# iom480ae register map
Registers are 32-bit, access not given, no defined reset value unless marked. A register's access mark holds for its fields unless they carry their own. Addresses are absolute; registers are grouped by the start of their names; [hi:lo] are bit positions; {n}, {i} and the like mark numbered series.

## QEI0
0x400B0000 QEI0_QEI_CNT
0x400B0004 QEI0_QEI_CNTHOLD
0x400B0008 QEI0_QEI_CNTLATCH
0x400B000C QEI0_QEI_CNTCMP
0x400B0014 QEI0_QEI_CNTMAX
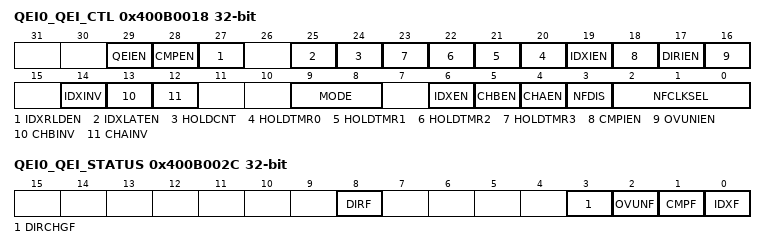
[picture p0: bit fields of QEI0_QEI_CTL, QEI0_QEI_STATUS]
0x400B0018 QEI0_QEI_CTL
  [29] QEIEN, [28] CMPEN, [27] IDXRLDEN, [25] IDXLATEN, [24] HOLDCNT, [n+20] HOLDTMR{n} (n=0..3), [19] IDXIEN, [18] CMPIEN, [17] DIRIEN, [16] OVUNIEN, [14] IDXINV, [13] CHBINV, [12] CHAINV, [9:8] MODE, [6] IDXEN, [5] CHBEN, [4] CHAEN, [3] NFDIS, [2:0] NFCLKSEL
0x400B002C QEI0_QEI_STATUS
  [8] DIRF, [3] DIRCHGF, [2] OVUNF, [1] CMPF, [0] IDXF

## QEI1
0x400B1000 QEI1_QEI_CNT
0x400B1004 QEI1_QEI_CNTHOLD
0x400B1008 QEI1_QEI_CNTLATCH
0x400B100C QEI1_QEI_CNTCMP
0x400B1014 QEI1_QEI_CNTMAX
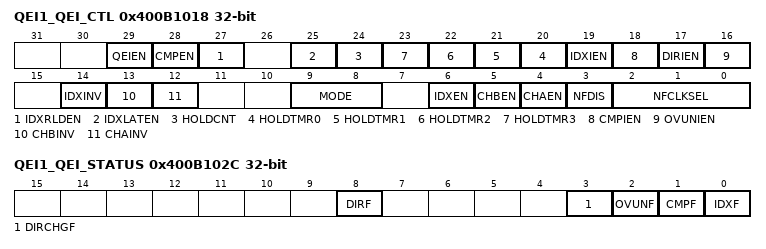
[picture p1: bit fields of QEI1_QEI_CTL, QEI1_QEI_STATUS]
0x400B1018 QEI1_QEI_CTL
  [29] QEIEN, [28] CMPEN, [27] IDXRLDEN, [25] IDXLATEN, [24] HOLDCNT, [n+20] HOLDTMR{n} (n=0..3), [19] IDXIEN, [18] CMPIEN, [17] DIRIEN, [16] OVUNIEN, [14] IDXINV, [13] CHBINV, [12] CHAINV, [9:8] MODE, [6] IDXEN, [5] CHBEN, [4] CHAEN, [3] NFDIS, [2:0] NFCLKSEL
0x400B102C QEI1_QEI_STATUS
  [8] DIRF, [3] DIRCHGF, [2] OVUNF, [1] CMPF, [0] IDXF

## ECAP0
0x400B4000 ECAP0_ECAP_CNT
  [23:0] CNT
{0x400B4004+4i} ECAP0_ECAP_HLD{i} (i=0..2)
  [23:0] HOLD
0x400B4010 ECAP0_ECAP_CNTCMP
  [23:0] CNTCMP
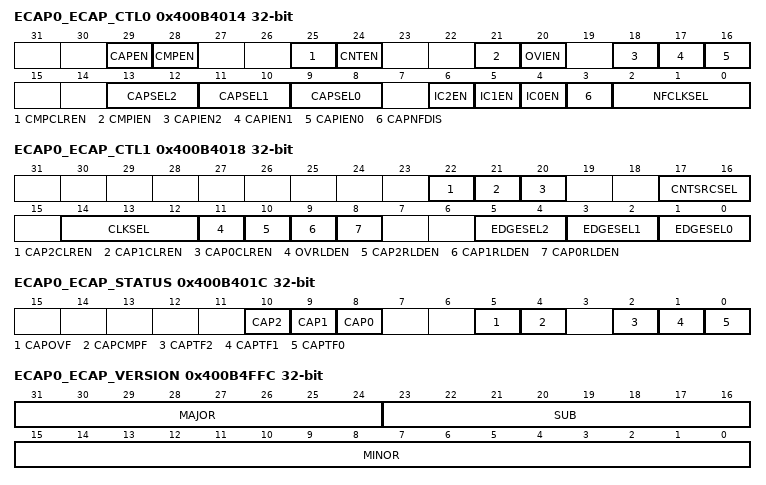
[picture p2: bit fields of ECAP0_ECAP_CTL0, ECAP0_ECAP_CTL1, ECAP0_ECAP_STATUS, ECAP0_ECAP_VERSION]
0x400B4014 ECAP0_ECAP_CTL0
  [29] CAPEN, [28] CMPEN, [25] CMPCLREN, [24] CNTEN, [21] CMPIEN, [20] OVIEN, [18] CAPIEN2, [17] CAPIEN1, [16] CAPIEN0, [13:12] CAPSEL2, [11:10] CAPSEL1, [9:8] CAPSEL0, [6] IC2EN, [5] IC1EN, [4] IC0EN, [3] CAPNFDIS, [2:0] NFCLKSEL
0x400B4018 ECAP0_ECAP_CTL1
  [22] CAP2CLREN, [21] CAP1CLREN, [20] CAP0CLREN, [17:16] CNTSRCSEL, [14:12] CLKSEL, [11] OVRLDEN, [10] CAP2RLDEN, [9] CAP1RLDEN, [8] CAP0RLDEN, [5:4] EDGESEL2, [3:2] EDGESEL1, [1:0] EDGESEL0
0x400B401C ECAP0_ECAP_STATUS
  [10] CAP2, [9] CAP1, [8] CAP0, [5] CAPOVF, [4] CAPCMPF, [2] CAPTF2, [1] CAPTF1, [0] CAPTF0
0x400B4FFC ECAP0_ECAP_VERSION
  [31:24] MAJOR, [23:16] SUB, [15:0] MINOR

## ECAP1
0x400B5000 ECAP1_ECAP_CNT
  [23:0] CNT
{0x400B5004+4i} ECAP1_ECAP_HLD{i} (i=0..2)
  [23:0] HOLD
0x400B5010 ECAP1_ECAP_CNTCMP
  [23:0] CNTCMP
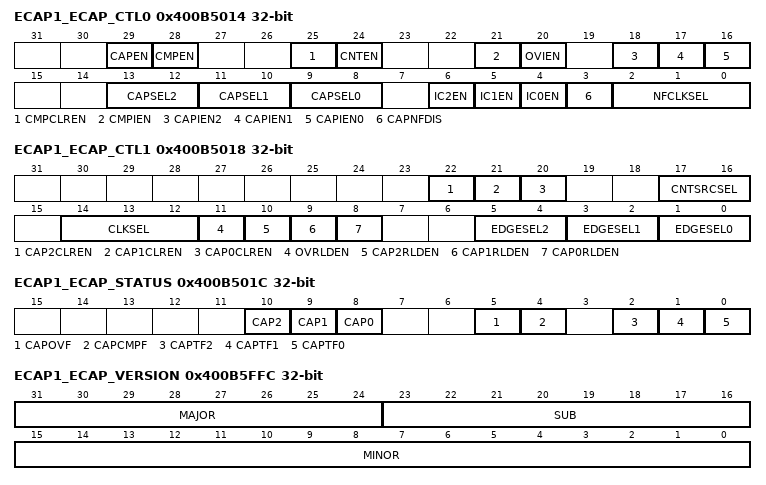
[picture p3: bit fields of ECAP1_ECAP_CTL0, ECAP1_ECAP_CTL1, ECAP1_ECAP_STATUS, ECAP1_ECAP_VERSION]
0x400B5014 ECAP1_ECAP_CTL0
  [29] CAPEN, [28] CMPEN, [25] CMPCLREN, [24] CNTEN, [21] CMPIEN, [20] OVIEN, [18] CAPIEN2, [17] CAPIEN1, [16] CAPIEN0, [13:12] CAPSEL2, [11:10] CAPSEL1, [9:8] CAPSEL0, [6] IC2EN, [5] IC1EN, [4] IC0EN, [3] CAPNFDIS, [2:0] NFCLKSEL
0x400B5018 ECAP1_ECAP_CTL1
  [22] CAP2CLREN, [21] CAP1CLREN, [20] CAP0CLREN, [17:16] CNTSRCSEL, [14:12] CLKSEL, [11] OVRLDEN, [10] CAP2RLDEN, [9] CAP1RLDEN, [8] CAP0RLDEN, [5:4] EDGESEL2, [3:2] EDGESEL1, [1:0] EDGESEL0
0x400B501C ECAP1_ECAP_STATUS
  [10] CAP2, [9] CAP1, [8] CAP0, [5] CAPOVF, [4] CAPCMPF, [2] CAPTF2, [1] CAPTF1, [0] CAPTF0
0x400B5FFC ECAP1_ECAP_VERSION
  [31:24] MAJOR, [23:16] SUB, [15:0] MINOR

## UART0
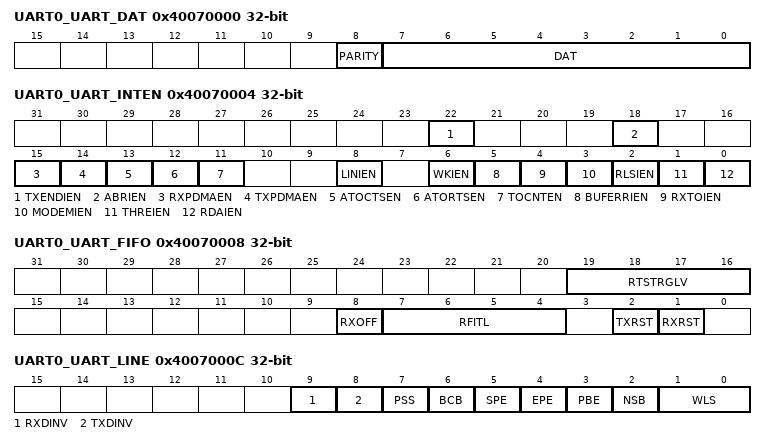
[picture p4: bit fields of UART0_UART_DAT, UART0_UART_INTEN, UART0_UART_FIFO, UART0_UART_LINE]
0x40070000 UART0_UART_DAT
  [8] PARITY, [7:0] DAT
0x40070004 UART0_UART_INTEN
  [22] TXENDIEN, [18] ABRIEN, [15] RXPDMAEN, [14] TXPDMAEN, [13] ATOCTSEN, [12] ATORTSEN, [11] TOCNTEN, [8] LINIEN, [6] WKIEN, [5] BUFERRIEN, [4] RXTOIEN, [3] MODEMIEN, [2] RLSIEN, [1] THREIEN, [0] RDAIEN
0x40070008 UART0_UART_FIFO
  [19:16] RTSTRGLV, [8] RXOFF, [7:4] RFITL, [2] TXRST, [1] RXRST
0x4007000C UART0_UART_LINE
  [9] RXDINV, [8] TXDINV, [7] PSS, [6] BCB, [5] SPE, [4] EPE, [3] PBE, [2] NSB, [1:0] WLS
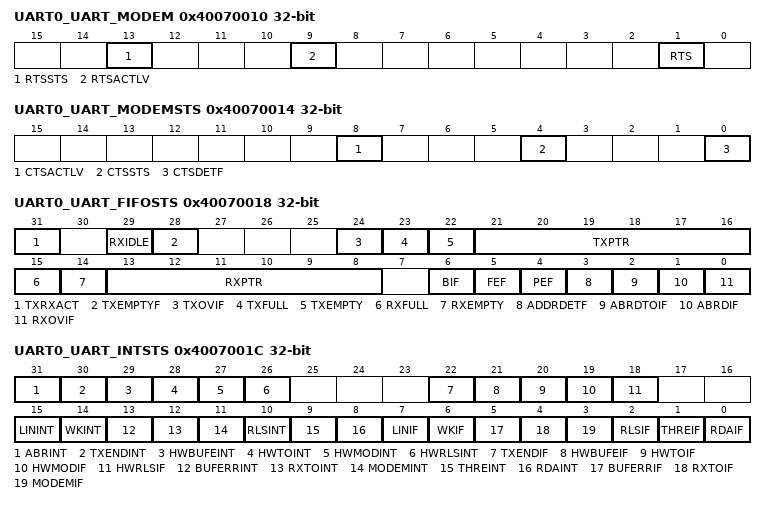
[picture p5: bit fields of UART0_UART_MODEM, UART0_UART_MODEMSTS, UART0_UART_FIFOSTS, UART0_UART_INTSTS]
0x40070010 UART0_UART_MODEM
  [13] RTSSTS, [9] RTSACTLV, [1] RTS
0x40070014 UART0_UART_MODEMSTS
  [8] CTSACTLV, [4] CTSSTS, [0] CTSDETF
0x40070018 UART0_UART_FIFOSTS
  [31] TXRXACT, [29] RXIDLE, [28] TXEMPTYF, [24] TXOVIF, [23] TXFULL, [22] TXEMPTY, [21:16] TXPTR, [15] RXFULL, [14] RXEMPTY, [13:8] RXPTR, [6] BIF, [5] FEF, [4] PEF, [3] ADDRDETF, [2] ABRDTOIF, [1] ABRDIF, [0] RXOVIF
0x4007001C UART0_UART_INTSTS
  [31] ABRINT, [30] TXENDINT, [29] HWBUFEINT, [28] HWTOINT, [27] HWMODINT, [26] HWRLSINT, [22] TXENDIF, [21] HWBUFEIF, [20] HWTOIF, [19] HWMODIF, [18] HWRLSIF, [15] LININT, [14] WKINT, [13] BUFERRINT, [12] RXTOINT, [11] MODEMINT, [10] RLSINT, [9] THREINT, [8] RDAINT, [7] LINIF, [6] WKIF, [5] BUFERRIF, [4] RXTOIF, [3] MODEMIF, [2] RLSIF, [1] THREIF, [0] RDAIF
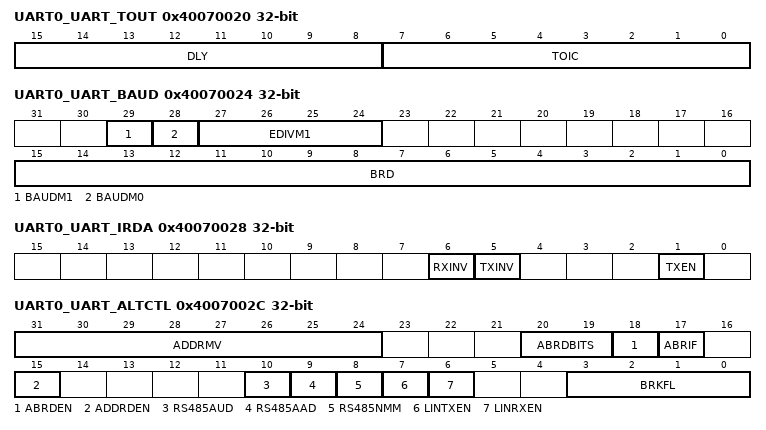
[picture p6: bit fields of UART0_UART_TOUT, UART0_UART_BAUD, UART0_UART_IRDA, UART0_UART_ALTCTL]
0x40070020 UART0_UART_TOUT
  [15:8] DLY, [7:0] TOIC
0x40070024 UART0_UART_BAUD
  [29] BAUDM1, [28] BAUDM0, [27:24] EDIVM1, [15:0] BRD
0x40070028 UART0_UART_IRDA
  [6] RXINV, [5] TXINV, [1] TXEN
0x4007002C UART0_UART_ALTCTL
  [31:24] ADDRMV, [20:19] ABRDBITS, [18] ABRDEN, [17] ABRIF, [15] ADDRDEN, [10] RS485AUD, [9] RS485AAD, [8] RS485NMM, [7] LINTXEN, [6] LINRXEN, [3:0] BRKFL
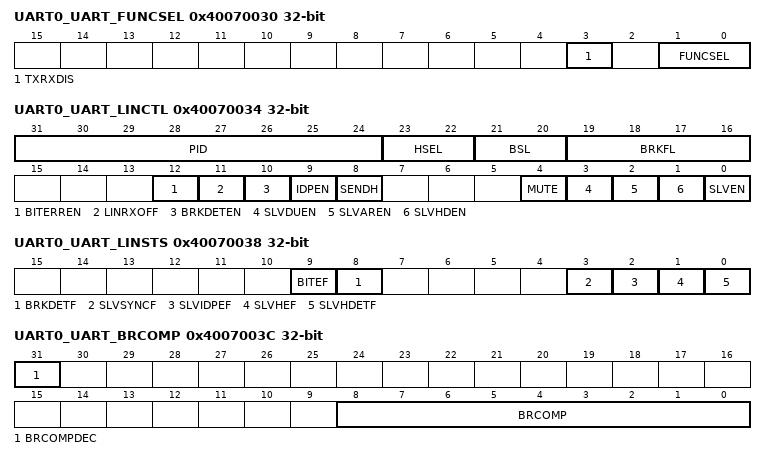
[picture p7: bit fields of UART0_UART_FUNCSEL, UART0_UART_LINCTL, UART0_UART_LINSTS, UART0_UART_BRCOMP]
0x40070030 UART0_UART_FUNCSEL
  [3] TXRXDIS, [1:0] FUNCSEL
0x40070034 UART0_UART_LINCTL
  [31:24] PID, [23:22] HSEL, [21:20] BSL, [19:16] BRKFL, [12] BITERREN, [11] LINRXOFF, [10] BRKDETEN, [9] IDPEN, [8] SENDH, [4] MUTE, [3] SLVDUEN, [2] SLVAREN, [1] SLVHDEN, [0] SLVEN
0x40070038 UART0_UART_LINSTS
  [9] BITEF, [8] BRKDETF, [3] SLVSYNCF, [2] SLVIDPEF, [1] SLVHEF, [0] SLVHDETF
0x4007003C UART0_UART_BRCOMP
  [31] BRCOMPDEC, [8:0] BRCOMP
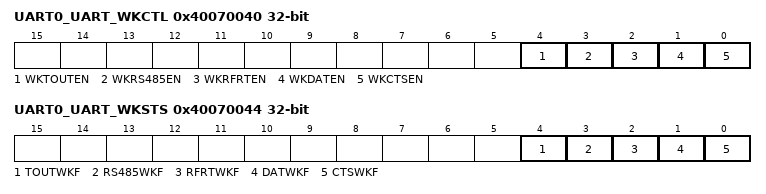
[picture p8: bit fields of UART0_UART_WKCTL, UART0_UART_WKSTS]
0x40070040 UART0_UART_WKCTL
  [4] WKTOUTEN, [3] WKRS485EN, [2] WKRFRTEN, [1] WKDATEN, [0] WKCTSEN
0x40070044 UART0_UART_WKSTS
  [4] TOUTWKF, [3] RS485WKF, [2] RFRTWKF, [1] DATWKF, [0] CTSWKF
0x40070048 UART0_UART_DWKCOMP
  [15:0] STCOMP
